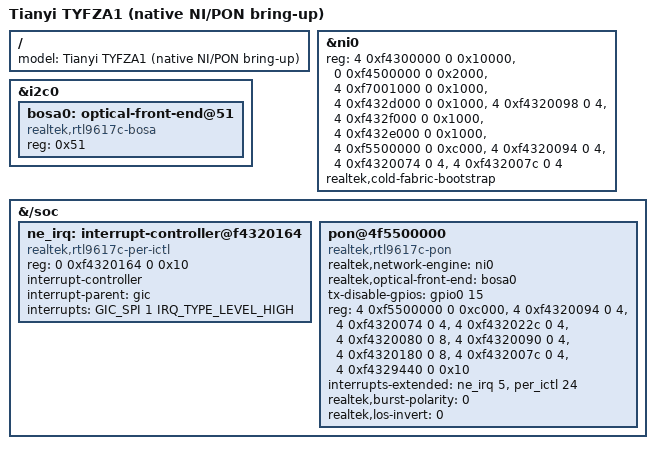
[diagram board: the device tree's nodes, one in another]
// SPDX-License-Identifier: GPL-2.0-only
#include "rtl9617c-tyfza1-ni.dts"
#include <dt-bindings/gpio/gpio.h>

/ { model = "Tianyi TYFZA1 (native NI/PON bring-up)"; };

/* NI owns the bounded cold transition before publishing any port. These
 * temporary leases are released before PON can bind; no PON phandle is
 * introduced here (PON already depends on NI). GPIO/BOSA/optical IRQ probe
 * cannot withhold LANs. No automatic L2 admission: bridge policy remains
 * separately requested through l2_switch after this baseline is ready. */
&ni0 {
	reg = <4 0xf4300000 0 0x10000>, <0 0xf4500000 0 0x2000>,
	      <4 0xf7001000 0 0x1000>, <4 0xf432d000 0 0x1000>,
	      <4 0xf4320098 0 4>, <4 0xf432f000 0 0x1000>,
	      <4 0xf432e000 0 0x1000>, <4 0xf5500000 0 0xc000>,
	      <4 0xf4320094 0 4>, <4 0xf4320074 0 4>, <4 0xf432007c 0 4>;
	reg-names = "ni", "xram", "dma-lso", "qm-axi-reorder", "block-reset",
		    "l3fe-axi-reorder", "dma-axi-reorder", "pon-cold-mac",
		    "pon-cold-control", "pon-cold-epon", "pon-cold-gpon";
	realtek,cold-fabric-bootstrap;
};

&i2c0 {
	status = "okay";
	bosa0: optical-front-end@51 {
		compatible = "realtek,rtl9617c-bosa";
		reg = <0x51>;
	};
};

&{/soc} {
	ne_irq: interrupt-controller@f4320164 {
		compatible = "realtek,rtl9617c-per-ictl", "cortina,per-ictl";
		reg = <0 0xf4320164 0 0x10>;
		interrupt-controller;
		#interrupt-cells = <1>;
		#address-cells = <0>;
		interrupt-parent = <&gic>;
		interrupts = <GIC_SPI 1 IRQ_TYPE_LEVEL_HIGH>;
	};

	pon@4f5500000 {
		compatible = "realtek,rtl9617c-pon";
		realtek,network-engine = <&ni0>;
		realtek,optical-front-end = <&bosa0>;
		tx-disable-gpios = <&gpio0 15 GPIO_ACTIVE_HIGH>;
		reg = <4 0xf5500000 0 0xc000>, <4 0xf4320094 0 4>,
		      <4 0xf4320074 0 4>, <4 0xf432022c 0 4>,
		      <4 0xf4320080 0 8>, <4 0xf4320090 0 4>, <4 0xf4320180 0 8>, <4 0xf432007c 0 4>,
		      <4 0xf4329440 0 0x10>;
		reg-names = "mac", "control", "epon-control", "serdes-init", "optical-control", "optical-status", "top-irq", "gpon-control", "dying-gasp";
		interrupts-extended = <&ne_irq 5>, <&per_ictl 24>;
		interrupt-names = "pon", "dying-gasp";
		realtek,burst-polarity = <0>;
		realtek,los-invert = <0>;
	};
};
